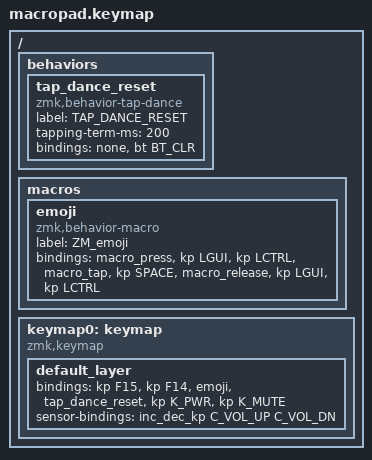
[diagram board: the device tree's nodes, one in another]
#include <dt-bindings/zmk/bt.h>
#include <behaviors.dtsi>
#include <dt-bindings/zmk/keys.h>


/ {
  behaviors {
      tap_dance_reset: tap_dance_reset {
          compatible = "zmk,behavior-tap-dance";
          label = "TAP_DANCE_RESET";
          #binding-cells = <0>;
          tapping-term-ms = <200>;
          bindings = <&none>, <&bt BT_CLR>;
      };
  };
  macros {
    emoji: emoji {
        label = "ZM_emoji";
        compatible = "zmk,behavior-macro";
        #binding-cells = <0>;
        bindings
            = <&macro_press &kp LGUI &kp LCTRL>
            , <&macro_tap &kp SPACE>
            , <&macro_release &kp LGUI &kp LCTRL>
            ;
    };
  };
	keymap0: keymap {
		compatible = "zmk,keymap";

    default_layer {
        bindings = <
          &kp F15    &kp F14    &emoji    &tap_dance_reset    &kp K_PWR    &kp K_MUTE
        >;

        sensor-bindings = <&inc_dec_kp C_VOL_UP C_VOL_DN>;
    };
  };
};
